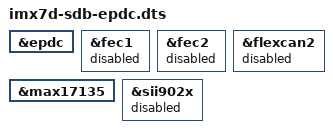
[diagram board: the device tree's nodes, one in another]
/*
 * Copyright (C) 2015 Freescale Semiconductor, Inc.
 *
 * This program is free software; you can redistribute it and/or modify
 * it under the terms of the GNU General Public License version 2 as
 * published by the Free Software Foundation.
 */

#include "imx7d-sdb.dts"

&epdc {
        status = "okay";
};

&fec1 {
	status = "disabled";
};

&fec2 {
	status = "disabled";
};

&flexcan2 {
	status = "disabled";
};

&max17135 {
        status = "okay";
};

&sii902x {
	status = "disabled";
};
